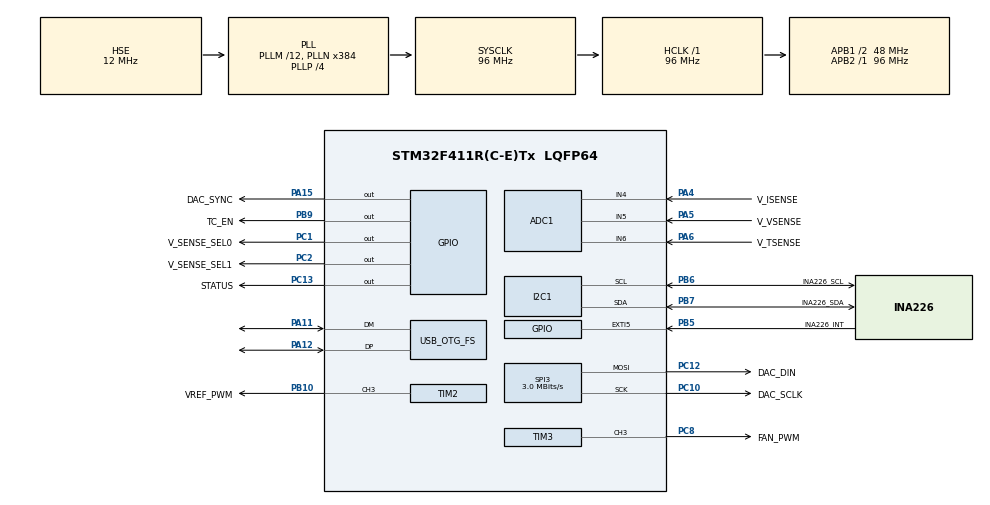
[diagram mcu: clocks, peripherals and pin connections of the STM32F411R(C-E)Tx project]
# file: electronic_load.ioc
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ADC1.Channel-0\#ChannelRegularConversion=ADC_CHANNEL_4
ADC1.Channel-1\#ChannelRegularConversion=ADC_CHANNEL_5
ADC1.Channel-2\#ChannelRegularConversion=ADC_CHANNEL_6
ADC1.NbrOfConversion=3
ADC1.NbrOfConversionFlag=1
ADC1.Rank-0\#ChannelRegularConversion=1
ADC1.Rank-1\#ChannelRegularConversion=2
ADC1.Rank-2\#ChannelRegularConversion=3
ADC1.SamplingTime-0\#ChannelRegularConversion=ADC_SAMPLETIME_15CYCLES
ADC1.SamplingTime-1\#ChannelRegularConversion=ADC_SAMPLETIME_15CYCLES
ADC1.SamplingTime-2\#ChannelRegularConversion=ADC_SAMPLETIME_15CYCLES
ADC1.master=1
Mcu.Family=STM32F4
Mcu.Name=STM32F411R(C-E)Tx
Mcu.Package=LQFP64
NVIC.EXTI9_5_IRQn=true\:2\:0\:false\:false\:true\:true\:true
NVIC.OTG_FS_IRQn=true\:0\:0\:false\:false\:true\:false\:true\:true
NVIC.PriorityGroup=NVIC_PRIORITYGROUP_4
PA11.Mode=Device_Only
PA11.Signal=USB_OTG_FS_DM
PA12.Mode=Device_Only
PA12.Signal=USB_OTG_FS_DP
PA13.Mode=Serial_Wire
PA13.Signal=SYS_JTMS-SWDIO
PA14.Mode=Serial_Wire
PA14.Signal=SYS_JTCK-SWCLK
PA15.GPIO_Label=DAC_SYNC
PA15.GPIO_OutputLevel=GPIO_PIN_SET
PA15.Signal=GPIO_Output
PA4.GPIO_Label=V_ISENSE
PA4.Signal=ADCx_IN4
PA5.GPIO_Label=V_VSENSE
PA5.Signal=ADCx_IN5
PA6.GPIO_Label=V_TSENSE
PA6.Signal=ADCx_IN6
PB10.GPIO_Label=VREF_PWM
PB10.Signal=S_TIM2_CH3
PB5.GPIO_Label=INA226_INT
PB5.GPIO_ModeDefaultEXTI=GPIO_MODE_IT_FALLING
PB5.GPIO_PuPd=GPIO_PULLUP
PB5.Signal=GPXTI5
PB6.GPIO_Label=INA226_SCL
PB6.GPIO_PuPd=GPIO_PULLUP
PB6.Mode=I2C
PB6.Signal=I2C1_SCL
PB7.GPIO_Label=INA226_SDA
PB7.GPIO_PuPd=GPIO_PULLUP
PB7.Mode=I2C
PB7.Signal=I2C1_SDA
PB9.GPIO_Label=TC_EN
PB9.Signal=GPIO_Output
PC1.GPIO_Label=V_SENSE_SEL0
PC1.Signal=GPIO_Output
PC10.GPIO_Label=DAC_SCLK
PC10.Mode=TX_Only_Simplex_Unidirect_Master
PC10.Signal=SPI3_SCK
PC12.GPIO_Label=DAC_DIN
PC12.Mode=TX_Only_Simplex_Unidirect_Master
PC12.Signal=SPI3_MOSI
PC13-ANTI_TAMP.GPIO_Label=STATUS
PC13-ANTI_TAMP.GPIO_OutputLevel=GPIO_PIN_SET
PC13-ANTI_TAMP.Signal=GPIO_Output
PC2.GPIO_Label=V_SENSE_SEL1
PC2.Signal=GPIO_Output
PC8.GPIO_Label=FAN_PWM
PC8.Signal=S_TIM3_CH3
PH0\ -\ OSC_IN.Mode=HSE-External-Oscillator
PH0\ -\ OSC_IN.Signal=RCC_OSC_IN
PH1\ -\ OSC_OUT.Mode=HSE-External-Oscillator
PH1\ -\ OSC_OUT.Signal=RCC_OSC_OUT
ProjectManager.HeapSize=0x200
ProjectManager.StackSize=0x400
ProjectManager.TargetToolchain=CMake
RCC.48MHZClocksFreq_Value=48000000
RCC.AHBFreq_Value=96000000
RCC.APB1CLKDivider=RCC_HCLK_DIV2
RCC.APB1Freq_Value=48000000
RCC.APB1TimFreq_Value=96000000
RCC.APB2Freq_Value=96000000
RCC.APB2TimFreq_Value=96000000
RCC.CortexFreq_Value=96000000
RCC.HCLKFreq_Value=96000000
RCC.HSE_VALUE=12000000
RCC.HSI_VALUE=16000000
RCC.LSE_VALUE=32768
RCC.PLLM=12
RCC.PLLN=384
RCC.PLLP=RCC_PLLP_DIV4
RCC.PLLQ=8
RCC.SYSCLKFreq_VALUE=96000000
RCC.SYSCLKSource=RCC_SYSCLKSOURCE_PLLCLK
RCC.VCOOutputFreq_Value=384000000
SH.ADCx_IN4.0=ADC1_IN4,IN4
SH.ADCx_IN5.0=ADC1_IN5,IN5
SH.ADCx_IN6.0=ADC1_IN6,IN6
SH.S_TIM2_CH3.0=TIM2_CH3,PWM Generation3 CH3
SH.S_TIM3_CH3.0=TIM3_CH3,PWM Generation3 CH3
SPI3.BaudRatePrescaler=SPI_BAUDRATEPRESCALER_16
SPI3.CLKPhase=SPI_PHASE_2EDGE
SPI3.CalculateBaudRate=3.0 MBits/s
SPI3.Direction=SPI_DIRECTION_1LINE
SPI3.Mode=SPI_MODE_MASTER
SPI3.VirtualType=VM_MASTER
TIM2.Channel-PWM\ Generation3\ CH3=TIM_CHANNEL_3
TIM2.Period=959
TIM2.Pulse-PWM\ Generation3\ CH3=364
TIM3.Channel-PWM\ Generation3\ CH3=TIM_CHANNEL_3
TIM3.Period=999
TIM3.Prescaler=95
TIM3.Pulse-PWM\ Generation3\ CH3=0
USB_DEVICE.CLASS_NAME_FS=CDC
USB_DEVICE.VirtualMode=Cdc
USB_DEVICE.VirtualModeFS=Cdc_FS
USB_OTG_FS.VirtualMode=Device_Only
VP_TIM2_VS_ClockSourceINT.Mode=Internal
VP_TIM3_VS_ClockSourceINT.Mode=Internal
VP_USB_DEVICE_VS_USB_DEVICE_CDC_FS.Mode=CDC_FS
board=custom

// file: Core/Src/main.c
/* USER CODE BEGIN Header */
/**
  ******************************************************************************
  * @file           : main.c
  * @brief          : Main program body
  ******************************************************************************
  * @attention
  *
  * Copyright (c) 2026 STMicroelectronics.
  * All rights reserved.
  *
  * This software is licensed under terms that can be found in the LICENSE file
  * in the root directory of this software component.
  * If no LICENSE file comes with this software, it is provided AS-IS.
  *
  ******************************************************************************
  */
/* USER CODE END Header */
#include "main.h"
#include "adc.h"
#include "i2c.h"
#include "spi.h"
#include "tim.h"
#include "usb_device.h"
#include "gpio.h"

/* USER CODE BEGIN Includes */
#include "lib/app/c_api.h"
/* USER CODE END Includes */

void SystemClock_Config(void);

int main(void)
{

  /* MCU Configuration--------------------------------------------------------*/

  /* Reset of all peripherals, Initializes the Flash interface and the Systick. */
  HAL_Init();

  /* Configure the system clock */
  SystemClock_Config();

  /* Initialize all configured peripherals */
  MX_GPIO_Init();
  MX_ADC1_Init();
  MX_I2C1_Init();
  MX_SPI3_Init();
  MX_TIM2_Init();
  MX_TIM3_Init();
  MX_USB_DEVICE_Init();
  /* USER CODE BEGIN 2 */
  electronicLoadInit();
  /* USER CODE END 2 */

  /* Infinite loop */
  while (1)
  {

    /* USER CODE BEGIN 3 */
    electronicLoadRunOnce();
  }
  /* USER CODE END 3 */
}

void SystemClock_Config(void)
{
  RCC_OscInitTypeDef RCC_OscInitStruct = {0};
  RCC_ClkInitTypeDef RCC_ClkInitStruct = {0};

  /** Configure the main internal regulator output voltage
  */
  __HAL_RCC_PWR_CLK_ENABLE();
  __HAL_PWR_VOLTAGESCALING_CONFIG(PWR_REGULATOR_VOLTAGE_SCALE1);

  /** Initializes the RCC Oscillators according to the specified parameters
  * in the RCC_OscInitTypeDef structure.
  */
  RCC_OscInitStruct.OscillatorType = RCC_OSCILLATORTYPE_HSE;
  RCC_OscInitStruct.HSEState = RCC_HSE_ON;
  RCC_OscInitStruct.PLL.PLLState = RCC_PLL_ON;
  RCC_OscInitStruct.PLL.PLLSource = RCC_PLLSOURCE_HSE;
  RCC_OscInitStruct.PLL.PLLM = 12;
  RCC_OscInitStruct.PLL.PLLN = 384;
  RCC_OscInitStruct.PLL.PLLP = RCC_PLLP_DIV4;
  RCC_OscInitStruct.PLL.PLLQ = 8;
  if (HAL_RCC_OscConfig(&RCC_OscInitStruct) != HAL_OK)
  {
    Error_Handler();
  }

  /** Initializes the CPU, AHB and APB buses clocks
  */
  RCC_ClkInitStruct.ClockType = RCC_CLOCKTYPE_HCLK|RCC_CLOCKTYPE_SYSCLK
                              |RCC_CLOCKTYPE_PCLK1|RCC_CLOCKTYPE_PCLK2;
  RCC_ClkInitStruct.SYSCLKSource = RCC_SYSCLKSOURCE_PLLCLK;
  RCC_ClkInitStruct.AHBCLKDivider = RCC_SYSCLK_DIV1;
  RCC_ClkInitStruct.APB1CLKDivider = RCC_HCLK_DIV2;
  RCC_ClkInitStruct.APB2CLKDivider = RCC_HCLK_DIV1;

  if (HAL_RCC_ClockConfig(&RCC_ClkInitStruct, FLASH_LATENCY_3) != HAL_OK)
  {
    Error_Handler();
  }
}

void Error_Handler(void)
{
  __disable_irq();
  while (1)
  {
  }
}
